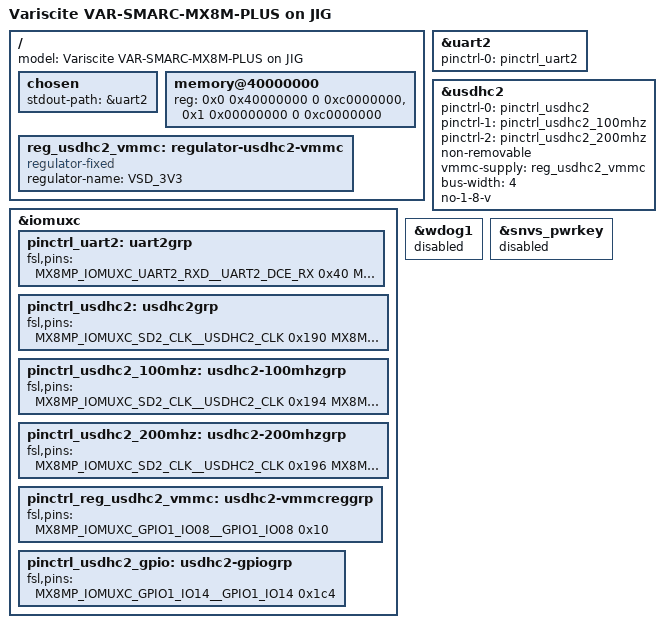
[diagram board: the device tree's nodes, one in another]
// SPDX-License-Identifier: (GPL-2.0+ OR MIT)
/*
 * Copyright 2019 NXP
 * Copyright 2026 Variscite Ltd.
 */

#include "imx8mp-var-smarc.dtsi"

/ {
	model = "Variscite VAR-SMARC-MX8M-PLUS on JIG";

	chosen {
		stdout-path = &uart2;
	};

	memory@40000000 {
		device_type = "memory";
		reg = <0x0 0x40000000 0 0xc0000000>,
		      <0x1 0x00000000 0 0xc0000000>;
	};

	reg_usdhc2_vmmc: regulator-usdhc2-vmmc {
		compatible = "regulator-fixed";
		regulator-name = "VSD_3V3";
	};
};

&uart2 {
	pinctrl-names = "default";
	pinctrl-0 = <&pinctrl_uart2>;
	status = "okay";
};

&usdhc2 {
	pinctrl-names = "default", "state_100mhz", "state_200mhz";
	pinctrl-0 = <&pinctrl_usdhc2>;
	pinctrl-1 = <&pinctrl_usdhc2_100mhz>;
	pinctrl-2 = <&pinctrl_usdhc2_200mhz>;
	non-removable;
	vmmc-supply = <&reg_usdhc2_vmmc>;
	bus-width = <4>;
	no-1-8-v;
	status = "okay";
};

&iomuxc {
	pinctrl_uart2: uart2grp {
		fsl,pins = <
			MX8MP_IOMUXC_UART2_RXD__UART2_DCE_RX				0x40
			MX8MP_IOMUXC_UART2_TXD__UART2_DCE_TX				0x40
		>;
	};

	pinctrl_usdhc2: usdhc2grp {
		fsl,pins = <
			MX8MP_IOMUXC_SD2_CLK__USDHC2_CLK				0x190
			MX8MP_IOMUXC_SD2_CMD__USDHC2_CMD				0x1d0
			MX8MP_IOMUXC_SD2_DATA0__USDHC2_DATA0				0x1d0
			MX8MP_IOMUXC_SD2_DATA1__USDHC2_DATA1				0x1d0
			MX8MP_IOMUXC_SD2_DATA2__USDHC2_DATA2				0x1d0
			MX8MP_IOMUXC_SD2_DATA3__USDHC2_DATA3				0x1d0
		>;
	};

	pinctrl_usdhc2_100mhz: usdhc2-100mhzgrp {
		fsl,pins = <
			MX8MP_IOMUXC_SD2_CLK__USDHC2_CLK				0x194
			MX8MP_IOMUXC_SD2_CMD__USDHC2_CMD				0x1d4
			MX8MP_IOMUXC_SD2_DATA0__USDHC2_DATA0				0x1d4
			MX8MP_IOMUXC_SD2_DATA1__USDHC2_DATA1				0x1d4
			MX8MP_IOMUXC_SD2_DATA2__USDHC2_DATA2				0x1d4
			MX8MP_IOMUXC_SD2_DATA3__USDHC2_DATA3				0x1d4
		>;
	};

	pinctrl_usdhc2_200mhz: usdhc2-200mhzgrp {
		fsl,pins = <
			MX8MP_IOMUXC_SD2_CLK__USDHC2_CLK				0x196
			MX8MP_IOMUXC_SD2_CMD__USDHC2_CMD				0x1d6
			MX8MP_IOMUXC_SD2_DATA0__USDHC2_DATA0				0x1d6
			MX8MP_IOMUXC_SD2_DATA1__USDHC2_DATA1				0x1d6
			MX8MP_IOMUXC_SD2_DATA2__USDHC2_DATA2				0x1d6
			MX8MP_IOMUXC_SD2_DATA3__USDHC2_DATA3				0x1d6
		>;
	};

	pinctrl_reg_usdhc2_vmmc: usdhc2-vmmcreggrp {
		fsl,pins = <
			MX8MP_IOMUXC_GPIO1_IO08__GPIO1_IO08				0x10
		>;
	};

	pinctrl_usdhc2_gpio: usdhc2-gpiogrp {
		fsl,pins = <
			MX8MP_IOMUXC_GPIO1_IO14__GPIO1_IO14				0x1c4
		>;
	};
};

&wdog1 {
	status = "disabled";
};

&snvs_pwrkey {
	status = "disabled";
};
